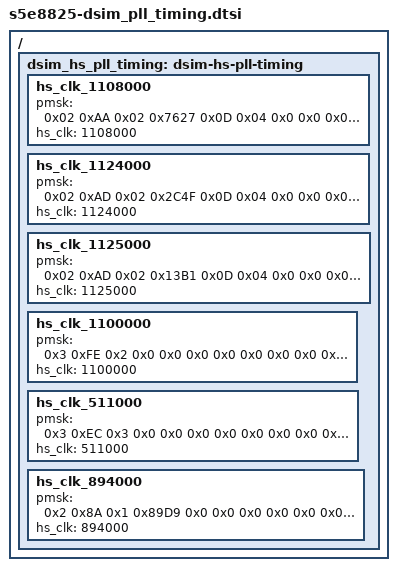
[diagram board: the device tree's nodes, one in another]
/*
 * SAMSUNG Panel Device Tree Source
 *
 * Copyright (c) 2017 Samsung Electronics Co., Ltd.
 *		http://www.samsung.com
 *
 * This program is free software; you can redistribute it and/or modify
 * it under the terms of the GNU General Public License version 2 as
 * published by the Free Software Foundation.
 */

/ {
	fragment@dsim_hs_pll_timing {
		target-path = "/";
		__overlay__ {
			dsim_hs_pll_timing: dsim-hs-pll-timing {
				hs_clk_1108000 {
					pmsk = <
						0x02 0xAA 0x02 0x7627
						0x0D 0x04 0x0 0x0
						0x0 0x0 0x0 0x0
						0x0 0x0
						>;
					hs_clk = <1108000>;
				};

				hs_clk_1124000 {
					pmsk = <
						0x02 0xAD 0x02 0x2C4F
						0x0D 0x04 0x0 0x0
						0x0 0x0 0x0 0x0
						0x0 0x0
						>;
					hs_clk = <1124000>;
				};

				hs_clk_1125000 {
					pmsk = <
						0x02 0xAD 0x02 0x13B1
						0x0D 0x04 0x0 0x0
						0x0 0x0 0x0 0x0
						0x0 0x0
						>;
					hs_clk = <1125000>;
				};

				hs_clk_1100000 {
					pmsk = <
						0x3 0xFE 0x2 0x0 /* p m s k */
						0x0 0x0 0x0 0x0
						0x0 0x0 0x0 0x0
						0x0 0x0
						>;
					hs_clk = <1100000>;
				};

				hs_clk_511000 {
					pmsk = <
						0x3 0xEC 0x3 0x0 /* p m s k */
						0x0 0x0 0x0 0x0
						0x0 0x0 0x0 0x0
						0x0 0x0
						>;
					hs_clk = <511000>;
				};

				hs_clk_894000 {
					pmsk = <
						0x2 0x8A 0x1 0x89D9 /* p m s k */
						0x0 0x0 0x0 0x0
						0x0 0x0 0x0 0x0
						0x0 0x0
						>;
					hs_clk = <894000>;
				};
			};
		};
	};
};
